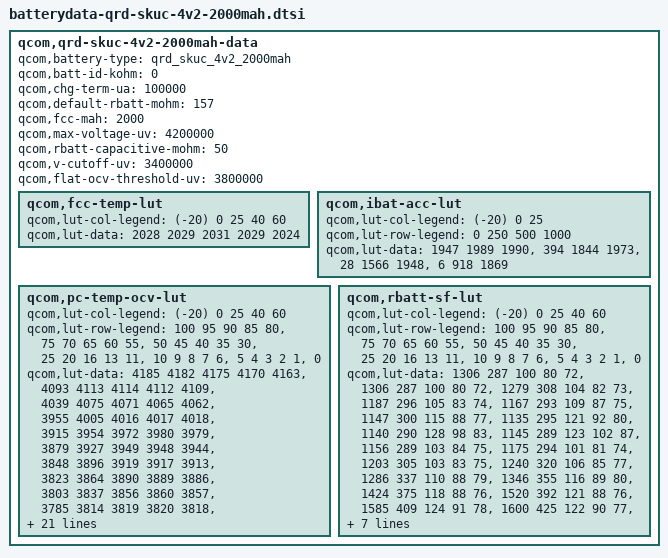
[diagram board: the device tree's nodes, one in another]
/* Copyright (c) 2014, The Linux Foundation. All rights reserved.
 *
 * This program is free software; you can redistribute it and/or modify
 * it under the terms of the GNU General Public License version 2 and
 * only version 2 as published by the Free Software Foundation.
 *
 * This program is distributed in the hope that it will be useful,
 * but WITHOUT ANY WARRANTY; without even the implied warranty of
 * MERCHANTABILITY or FITNESS FOR A PARTICULAR PURPOSE.  See the
 * GNU General Public License for more details.
 */

qcom,qrd-skuc-4v2-2000mah-data {
	qcom,battery-type = "qrd_skuc_4v2_2000mah";
	qcom,batt-id-kohm = <0>;
	qcom,chg-term-ua = <100000>;
	qcom,default-rbatt-mohm = <157>;
	qcom,fcc-mah = <2000>;
	qcom,max-voltage-uv = <4200000>;
	qcom,rbatt-capacitive-mohm = <50>;
	qcom,v-cutoff-uv = <3400000>;
	qcom,flat-ocv-threshold-uv = <3800000>;

	qcom,fcc-temp-lut {
		qcom,lut-col-legend = <(-20) 0 25 40 60>;
		qcom,lut-data = <2028 2029 2031 2029 2024>;
	};

	qcom,ibat-acc-lut {
		qcom,lut-col-legend = <(-20) 0 25>;
		qcom,lut-row-legend = <0 250 500 1000>;
		qcom,lut-data = <1947 1989 1990>,
				<394 1844 1973>,
				<28 1566 1948>,
				<6 918 1869>;
	};

	qcom,pc-temp-ocv-lut {
		qcom,lut-col-legend = <(-20) 0 25 40 60>;
		qcom,lut-row-legend = <100 95 90 85 80>,
					<75 70 65 60 55>,
					<50 45 40 35 30>,
					<25 20 16 13 11>,
					<10 9 8 7 6>,
					<5 4 3 2 1>,
					<0>;
		qcom,lut-data = <4185 4182 4175 4170 4163>,
				<4093 4113 4114 4112 4109>,
				<4039 4075 4071 4065 4062>,
				<3955 4005 4016 4017 4018>,
				<3915 3954 3972 3980 3979>,
				<3879 3927 3949 3948 3944>,
				<3848 3896 3919 3917 3913>,
				<3823 3864 3890 3889 3886>,
				<3803 3837 3856 3860 3857>,
				<3785 3814 3819 3820 3818>,
				<3769 3796 3799 3799 3797>,
				<3754 3785 3786 3785 3783>,
				<3740 3776 3777 3775 3773>,
				<3725 3769 3772 3769 3765>,
				<3710 3759 3767 3762 3755>,
				<3696 3746 3757 3749 3734>,
				<3677 3725 3739 3730 3715>,
				<3657 3707 3715 3708 3694>,
				<3636 3695 3693 3686 3674>,
				<3618 3687 3685 3679 3668>,
				<3604 3682 3683 3678 3667>,
				<3586 3676 3681 3676 3666>,
				<3565 3669 3677 3673 3664>,
				<3538 3660 3672 3669 3659>,
				<3505 3644 3662 3659 3648>,
				<3465 3615 3637 3633 3619>,
				<3420 3561 3585 3581 3566>,
				<3366 3485 3507 3505 3491>,
				<3292 3392 3405 3403 3389>,
				<3177 3269 3273 3267 3247>,
				<3000 3000 3000 3000 3000>;
	};

	qcom,rbatt-sf-lut {
		qcom,lut-col-legend = <(-20) 0 25 40 60>;
		qcom,lut-row-legend = <100 95 90 85 80>,
					<75 70 65 60 55>,
					<50 45 40 35 30>,
					<25 20 16 13 11>,
					<10 9 8 7 6>,
					<5 4 3 2 1>,
					<0>;
		qcom,lut-data = <1306 287 100 80 72>,
				<1306 287 100 80 72>,
				<1279 308 104 82 73>,
				<1187 296 105 83 74>,
				<1167 293 109 87 75>,
				<1147 300 115 88 77>,
				<1135 295 121 92 80>,
				<1140 290 128 98 83>,
				<1145 289 123 102 87>,
				<1156 289 103 84 75>,
				<1175 294 101 81 74>,
				<1203 305 103 83 75>,
				<1240 320 106 85 77>,
				<1286 337 110 88 79>,
				<1346 355 116 89 80>,
				<1424 375 118 88 76>,
				<1520 392 121 88 76>,
				<1585 409 124 91 78>,
				<1600 425 122 90 77>,
				<1470 402 117 88 77>,
				<1520 414 120 90 78>,
				<1614 429 125 94 80>,
				<1799 447 132 97 82>,
				<2021 465 141 101 83>,
				<2321 483 151 104 83>,
				<2785 493 155 105 81>,
				<3481 491 154 107 84>,
				<4527 503 153 109 88>,
				<6542 563 152 111 91>,
				<12962 745 165 118 95>,
				<194170 31358 37864 86058 77785>;
	};
};
